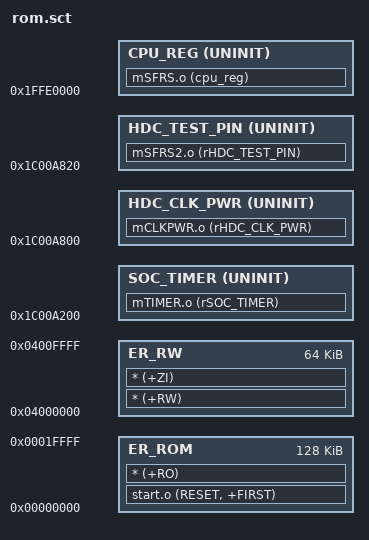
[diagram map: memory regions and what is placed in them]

LR_ROM 0x0 0x20000 
{
	ER_ROM 0x0 0x20000
	{
		start.o (RESET, +FIRST)
		* (+RO)
	}

	ER_RW 0x04000000 0x10000
	{
		* (+RW)
		* (+ZI)
	}
}

LR_REG 0x1C000000
{
	; rCLKPWR
	HDC_CLK_PWR	0x1C00A800 UNINIT
	{
		mCLKPWR.o (rHDC_CLK_PWR)
	}

	; rTimer
 	SOC_TIMER	0x1C00A200 UNINIT 
	{
		mTIMER.o (rSOC_TIMER)
	}

	; rCPU
	CPU_REG		0x1FFE0000 UNINIT
	{
		mSFRS.o (cpu_reg)
	}

	; rSFRS2
 	HDC_TEST_PIN	0x1C00A820 UNINIT 
	{
		mSFRS2.o (rHDC_TEST_PIN)
	}

}

